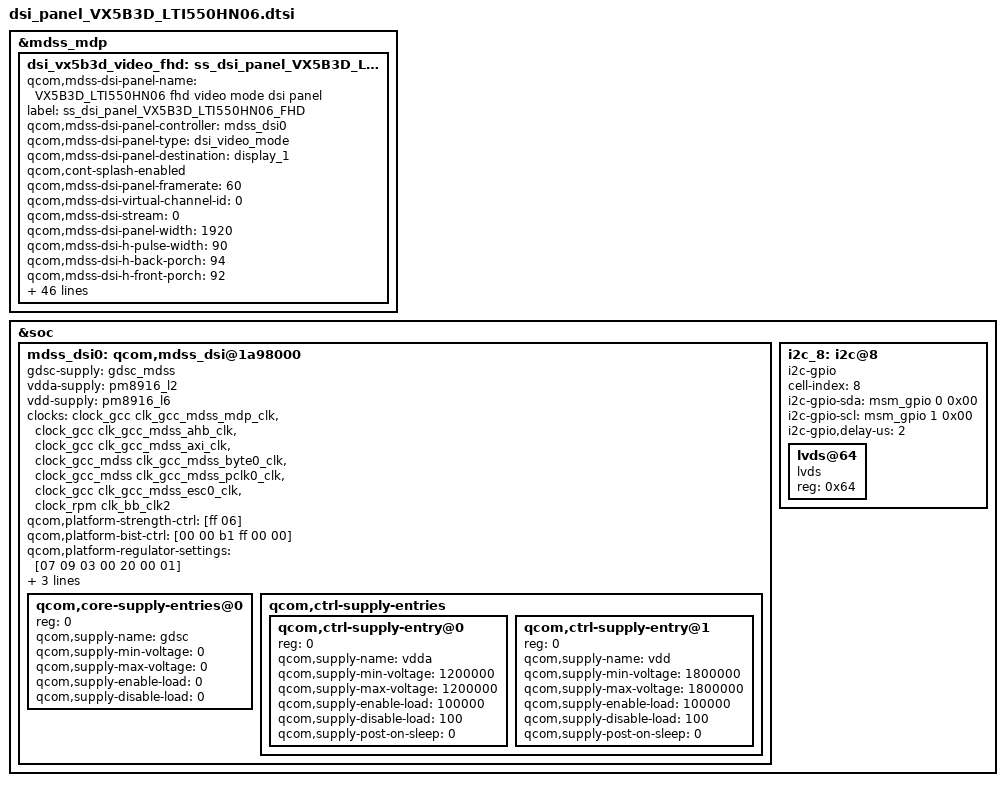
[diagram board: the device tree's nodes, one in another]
/* Copyright (c) 2013, The Linux Foundation. All rights reserved.
 *
 * This program is free software; you can redistribute it and/or modify
 * it under the terms of the GNU General Public License version 2 and
 * only version 2 as published by the Free Software Foundation.
 *
 * This program is distributed in the hope that it will be useful,
 * but WITHOUT ANY WARRANTY; without even the implied warranty of
 * MERCHANTABILITY or FITNESS FOR A PARTICULAR PURPOSE.  See the
 * GNU General Public License for more details.
 */

/*---------------------------------------------------------------------------
 * This file is autogenerated file using gcdb parser. Please do not edit it.
 * Update input XML file to add a new entry or update variable in this file
 * VERSION = "1.0"
 *---------------------------------------------------------------------------*/
&mdss_mdp {
	dsi_vx5b3d_video_fhd: ss_dsi_panel_VX5B3D_LTI550HN06_FHD {
		qcom,mdss-dsi-panel-name = "VX5B3D_LTI550HN06 fhd video mode dsi panel";
		label = "ss_dsi_panel_VX5B3D_LTI550HN06_FHD";
		qcom,mdss-dsi-panel-controller = <&mdss_dsi0>;
		qcom,mdss-dsi-panel-type = "dsi_video_mode";
		qcom,mdss-dsi-panel-destination = "display_1";

		qcom,cont-splash-enabled;
		qcom,mdss-dsi-panel-framerate = <60>;
		qcom,mdss-dsi-virtual-channel-id = <0>;
		qcom,mdss-dsi-stream = <0>;
		qcom,mdss-dsi-panel-width = <1920>;

		qcom,mdss-dsi-h-pulse-width = <90>;
		qcom,mdss-dsi-h-back-porch = <94>;
		qcom,mdss-dsi-h-front-porch = <92>;

		qcom,mdss-dsi-h-sync-skew = <0>;

		qcom,mdss-dsi-panel-height = <1080>;
		qcom,mdss-dsi-v-pulse-width = <15>;
		qcom,mdss-dsi-v-back-porch = <15>;
		qcom,mdss-dsi-v-front-porch = <15>;

		qcom,mdss-dsi-panel-timings = [E6 38 26 00 68 6C 2A 3A 2C 03 04 00]; /*889.38M*/


		qcom,mdss-dsi-t-clk-post = <0x3>;
		qcom,mdss-dsi-t-clk-pre = <0x28>;

		qcom,mdss-dsi-h-left-border = <0>;
		qcom,mdss-dsi-h-right-border = <0>;
		qcom,mdss-dsi-v-top-border = <0>;
		qcom,mdss-dsi-v-bottom-border = <0>;
		qcom,mdss-dsi-bpp = <24>;
		qcom,mdss-dsi-underflow-color = <0xff>;
		qcom,mdss-dsi-border-color = <0>;
		qcom,mdss-dsi-on-command-state = "dsi_lp_mode";
		qcom,mdss-dsi-off-command-state = "dsi_hs_mode";
		samsung,support_panel_max = <1>;

		qcom,mdss-dsi-h-sync-pulse = <1>;
		qcom,mdss-dsi-bllp-eof-power-mode;
		qcom,mdss-dsi-bllp-power-mode;
		qcom,mdss-dsi-lane-0-state;
		qcom,mdss-dsi-lane-1-state;
		qcom,mdss-dsi-lane-2-state;
		qcom,mdss-dsi-lane-3-state;
		qcom,mdss-dsi-traffic-mode = "burst_mode";
		qcom,mdss-dsi-lane-map = <0>;
		qcom,mdss-dsi-bl-min-level = <1>;
		qcom,mdss-dsi-bl-max-level = <255>;
		qcom,mdss-dsi-dma-trigger = "trigger_sw";
		qcom,mdss-dsi-mdp-trigger = "none";
		qcom,mdss-force-clk-lane-hs = <1>;
		qcom,mdss-dsi-reset-sequence = <0 5>, <1 10>;
		qcom,mdss-pan-physical-width-dimension = <896>; /* ?<Width> real size of panel in mm */
		qcom,mdss-pan-physical-height-dimension = <504>; /*?<Height> real size of panel in mm */

		samsung,blic-discharging-delay-us = <1000000>;/*temp T4 -1s*/
		samsung,mdss-power-on-reset-delay-us = <1000>;
		samsung,mdss-dsi-off-reset-delay-us = <1000>;

		qcom,mdss-dsi-lp11-init;
		qcom,mdss-dsi-init-delay-us = <10>;
		samsung,tft-common-support;
		samsung,backlight-gpio-config;
		qcom,mdss-dsi-force-clk-lane-hs;
		qcom,mdss-dsi-bl-pmic-control-type = "bl_ctrl_ss_pwm";
	};
};

&mdss_dsi0 {
	qcom,dsi-pref-prim-pan = <&dsi_vx5b3d_video_fhd>;
};

&soc {
	mdss_dsi0: qcom,mdss_dsi@1a98000 {
		gdsc-supply = <&gdsc_mdss>;
		vdda-supply = <&pm8916_l2>;
		vdd-supply = <&pm8916_l6>;

		clocks = <&clock_gcc clk_gcc_mdss_mdp_clk>,
                         <&clock_gcc clk_gcc_mdss_ahb_clk>,
                         <&clock_gcc clk_gcc_mdss_axi_clk>,
                         <&clock_gcc_mdss clk_gcc_mdss_byte0_clk>,
                         <&clock_gcc_mdss clk_gcc_mdss_pclk0_clk>,
                         <&clock_gcc clk_gcc_mdss_esc0_clk>,
                         <&clock_rpm clk_bb_clk2>;
                clock-names = "mdp_core_clk", "iface_clk", "bus_clk",
                                "byte_clk", "pixel_clk", "core_clk","lvds_clk";

		qcom,platform-strength-ctrl = [ff 06];
		qcom,platform-bist-ctrl = [00 00 b1 ff 00 00];
		qcom,platform-regulator-settings = [07 09 03 00 20 00 01];
		qcom,platform-lane-config = [00 00 00 00 00 00 00 01 97
			00 00 00 00 05 00 00 01 97
			00 00 00 00 0a 00 00 01 97
			00 00 00 00 0f 00 00 01 97
			00 c0 00 00 00 00 00 01 bb];

		qcom,core-supply-entries@0 {
				reg = <0>;
				qcom,supply-name = "gdsc";
				qcom,supply-min-voltage = <0>;
				qcom,supply-max-voltage = <0>;
				qcom,supply-enable-load = <0>;
				qcom,supply-disable-load = <0>;
			};


		qcom,ctrl-supply-entries {
			#address-cells = <1>;
			#size-cells = <0>;

			qcom,ctrl-supply-entry@0 {
				reg = <0>;
				qcom,supply-name = "vdda";
				qcom,supply-min-voltage = <1200000>;
				qcom,supply-max-voltage = <1200000>;
				qcom,supply-enable-load = <100000>;
				qcom,supply-disable-load = <100>;
				qcom,supply-post-on-sleep = <0>;
			};
		};
		qcom,ctrl-supply-entries {
			#address-cells = <1>;
			#size-cells = <0>;

			qcom,ctrl-supply-entry@1 {
				reg = <0>;
				qcom,supply-name = "vdd";
				qcom,supply-min-voltage = <1800000>;
				qcom,supply-max-voltage = <1800000>;
				qcom,supply-enable-load = <100000>;
				qcom,supply-disable-load = <100>;
				qcom,supply-post-on-sleep = <0>;
			};
		};
	};

	/*once bringup, need to check*/
	i2c_8:i2c@8 {
		cell-index = <8>;
		compatible = "i2c-gpio";
		i2c-gpio-sda = <&msm_gpio 0 0x00>;
		i2c-gpio-scl = <&msm_gpio 1 0x00>;
		i2c-gpio,delay-us = <2>;
		#address-cells = <1>;
		#size-cells = <0>;

		lvds@64 {
			compatible = "lvds";
			reg = <0x64>;/*slave addr*/
		};
	};
};
